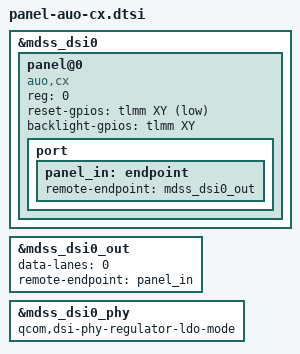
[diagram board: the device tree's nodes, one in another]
&mdss_dsi0 {
	panel@0 {
		compatible = "auo,cx";
		reg = <0>;

		reset-gpios = <&tlmm XY GPIO_ACTIVE_LOW>;
		backlight-gpios = <&tlmm XY GPIO_ACTIVE_HIGH>;

		port {
			panel_in: endpoint {
				remote-endpoint = <&mdss_dsi0_out>;
			};
		};
	};
};

&mdss_dsi0_out {
	data-lanes = <0>;
	remote-endpoint = <&panel_in>;
};

&mdss_dsi0_phy {
	qcom,dsi-phy-regulator-ldo-mode;
};
